VERSION ""

NS_ :

BS_:

BU_: CART BMS ACC LV INV

BO_ 57 Beacon: 2 Vector__XXX
 SG_ BeaconCount : 0|16@1+ (1,0) [0|0] "" Vector__XXX

BO_ 56 M056_Speed: 2 Vector__XXX
 SG_ LV_FILTERED_V : 0|16@1- (0.1,0) [-3276.8|3276.7] "" Vector__XXX

BO_ 54 M054_INV_Info: 4 Vector__XXX
 SG_ INV_DC_Bus_Voltage : 16|16@1- (0.1,0) [-3276.8|3276.7] "" Vector__XXX
 SG_ INV_DC_Bus_Current : 0|16@1- (0.1,0) [-3276.8|3276.7] "" Vector__XXX

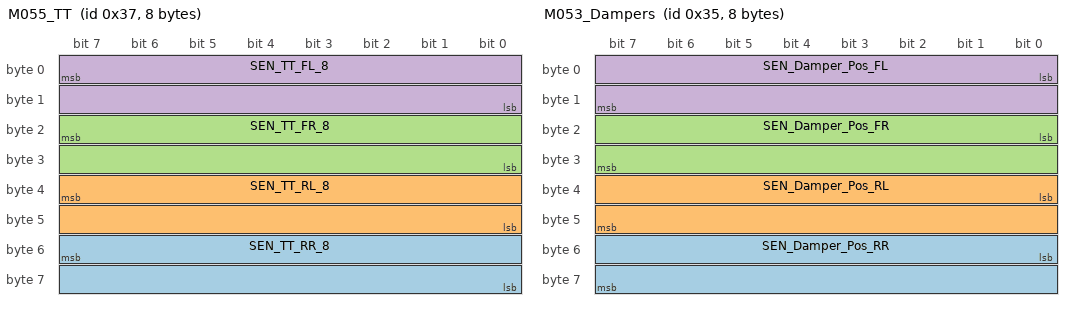
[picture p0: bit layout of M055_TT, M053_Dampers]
BO_ 55 M055_TT: 8 Vector__XXX
 SG_ SEN_TT_RR_8 : 55|16@0+ (0.1,0) [0|655.35] "" Vector__XXX
 SG_ SEN_TT_RL_8 : 39|16@0+ (0.1,0) [0|655.35] "" Vector__XXX
 SG_ SEN_TT_FR_8 : 23|16@0+ (0.1,0) [0|655.35] "" Vector__XXX
 SG_ SEN_TT_FL_8 : 7|16@0+ (0.1,0) [0|655.35] "" Vector__XXX

BO_ 53 M053_Dampers: 8 Vector__XXX
 SG_ SEN_Damper_Pos_RR : 48|16@1- (0.001,0) [0|0] "" Vector__XXX
 SG_ SEN_Damper_Pos_RL : 32|16@1- (0.001,0) [-32.768|32.767] "" Vector__XXX
 SG_ SEN_Damper_Pos_FR : 16|16@1- (0.001,0) [-32.768|32.767] "" Vector__XXX
 SG_ SEN_Damper_Pos_FL : 0|16@1- (0.001,0) [-32.768|32.767] "" Vector__XXX

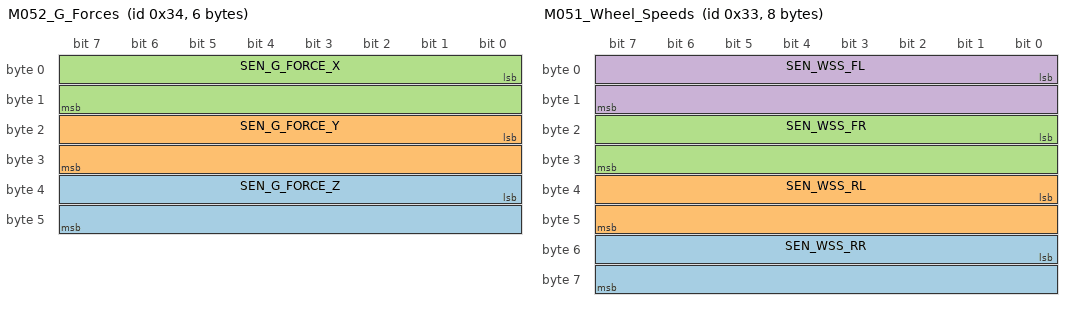
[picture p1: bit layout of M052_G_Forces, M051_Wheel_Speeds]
BO_ 52 M052_G_Forces: 6 Vector__XXX
 SG_ SEN_G_FORCE_Z : 32|16@1- (0.01,0) [-327.68|327.67] "" Vector__XXX
 SG_ SEN_G_FORCE_Y : 16|16@1- (0.01,0) [-327.68|327.67] "" Vector__XXX
 SG_ SEN_G_FORCE_X : 0|16@1- (0.01,0) [-327.68|327.67] "" Vector__XXX

BO_ 51 M051_Wheel_Speeds: 8 Vector__XXX
 SG_ SEN_WSS_RR : 48|16@1+ (0.1,0) [0|6553.5] "" Vector__XXX
 SG_ SEN_WSS_RL : 32|16@1+ (0.1,0) [0|6553.5] "" Vector__XXX
 SG_ SEN_WSS_FR : 16|16@1+ (0.1,0) [0|163.8375] "" Vector__XXX
 SG_ SEN_WSS_FL : 0|16@1+ (0.1,0) [0|6553.5] "" Vector__XXX

BO_ 215 M215_BMS_F: 5 BMS
 SG_ BMS_T_F1 : 32|8@1+ (0.25,0) [0|63.75] "temperature:C" Vector__XXX
 SG_ BMS_V_F1 : 0|8@1+ (0.01,1.8) [1.8|4.35] "voltage:V" Vector__XXX

BO_ 212 M212_BMS_E: 5 BMS
 SG_ BMS_T_E1 : 32|8@1+ (0.25,0) [0|63.75] "temperature:C" Vector__XXX
 SG_ BMS_V_E1 : 0|8@1+ (0.01,1.8) [1.8|4.35] "voltage:V" Vector__XXX

BO_ 209 M209_BMS_D: 5 BMS
 SG_ BMS_T_D1 : 32|8@1+ (0.25,0) [0|63.75] "temperature:C" Vector__XXX
 SG_ BMS_V_D1 : 0|8@1+ (0.01,1.8) [1.8|4.35] "voltage:V" Vector__XXX

BO_ 206 M206_BMS_C: 5 BMS
 SG_ BMS_T_C1 : 32|8@1+ (0.25,0) [0|63.75] "temperature:C" Vector__XXX
 SG_ BMS_V_C1 : 0|8@1+ (0.01,1.8) [1.8|4.35] "voltage:V" Vector__XXX

BO_ 203 M203_BMS_B: 8 BMS
 SG_ BMS_T_B1 : 32|8@1+ (0.25,0) [0|63.75] "temperature:C" Vector__XXX
 SG_ BMS_V_B1 : 0|8@1+ (0.01,1.8) [1.8|4.35] "voltage:V" Vector__XXX

BO_ 200 M200_BMS_A: 5 BMS
 SG_ BMS_T_A1 : 32|8@1+ (0.25,0) [0|63.75] "temperature:C" Vector__XXX
 SG_ BMS_V_A1 : 0|8@1+ (0.01,1.8) [1.8|4.35] "voltage:V" Vector__XXX

BO_ 1 M001_Vehicle_State: 1 LV
 SG_ LV_Vehicle_State : 0|8@1- (1,0) [0|0] "" Vector__XXX

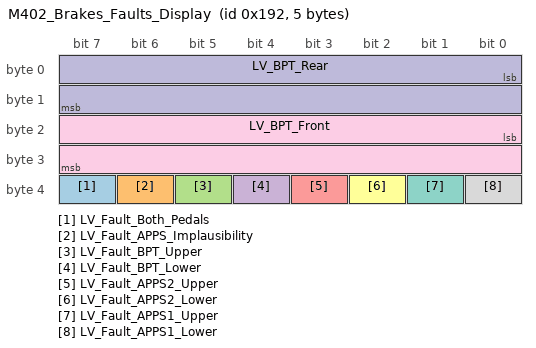
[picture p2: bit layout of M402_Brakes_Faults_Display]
BO_ 402 M402_Brakes_Faults_Display: 5 LV
 SG_ LV_Fault_Both_Pedals : 39|1@1+ (1,0) [0|1] "" Vector__XXX
 SG_ LV_Fault_APPS_Implausibility : 38|1@1+ (1,0) [0|1] "" Vector__XXX
 SG_ LV_Fault_BPT_Upper : 37|1@1+ (1,0) [0|1] "" Vector__XXX
 SG_ LV_Fault_BPT_Lower : 36|1@1+ (1,0) [0|1] "" Vector__XXX
 SG_ LV_Fault_APPS2_Upper : 35|1@1+ (1,0) [0|1] "" Vector__XXX
 SG_ LV_Fault_APPS2_Lower : 34|1@1+ (1,0) [0|1] "" Vector__XXX
 SG_ LV_Fault_APPS1_Upper : 33|1@1+ (1,0) [0|1] "" Vector__XXX
 SG_ LV_Fault_APPS1_Lower : 32|1@1+ (1,0) [0|1] "" Vector__XXX
 SG_ LV_BPT_Front : 16|16@1+ (1,0) [0|0] "" Vector__XXX
 SG_ LV_BPT_Rear : 0|16@1+ (1,0) [0|0] "" Vector__XXX

BO_ 156 M156_Torque_And_Timer_Info: 4 INV
 SG_ INV_Torque_Feedback : 16|16@1- (0.1,0) [-3276.8|3276.7] "torque:N.m" Vector__XXX
 SG_ INV_Commanded_Torque : 0|16@1- (0.1,0) [-3276.8|3276.7] "torque:N.m" Vector__XXX

BO_ 176 M176_Command_Message: 2 LV
 SG_ VCU_INV_Torque_Command : 0|16@1- (0.1,0) [-3276.8|3276.7] "torque:N.m" Vector__XXX

BO_ 149 M149_Motor_Position_Info: 4 INV
 SG_ INV_Motor_Speed : 16|16@1- (1,0) [-32768|32767] "angular_speed:rpm" Vector__XXX

CM_ SG_ 156 INV_Torque_Feedback "Estimated motor torque feedback";
CM_ SG_ 156 INV_Commanded_Torque "The commanded Torque";
CM_ BO_ 176 "The command message is used to transmit data to the controller. This message is sent from a user supplied external controller to the PMxxx controller.";
CM_ SG_ 176 VCU_INV_Torque_Command "Torque command when in torque mode";
CM_ SG_ 149 INV_Motor_Speed "The measured speed of the motor";
BA_DEF_ BO_  "GenMsgCycleTime" INT 0 100000;
BA_DEF_  "BusType" STRING ;
BA_DEF_DEF_  "GenMsgCycleTime" 0;
BA_DEF_DEF_  "BusType" "CAN";
BA_ "GenMsgCycleTime" BO_ 156 10;
BA_ "GenMsgCycleTime" BO_ 176 10;
BA_ "GenMsgCycleTime" BO_ 149 10;
